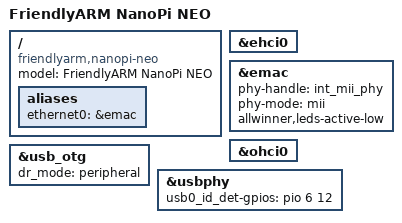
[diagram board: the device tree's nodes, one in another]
#include "sun8i-h3-nanopi.dtsi"
/ {
	model = "FriendlyARM NanoPi NEO";
	compatible = "friendlyarm,nanopi-neo", "allwinner,sun8i-h3";
	aliases {
		ethernet0 = &emac;
	};
};
&ehci0 {
	status = "okay";
};
&emac {
	phy-handle = <&int_mii_phy>;
	phy-mode = "mii";
	allwinner,leds-active-low;
	status = "okay";
};
&ohci0 {
	status = "okay";
};
&usb_otg {
	status = "okay";
	dr_mode = "peripheral";
};
&usbphy {
	usb0_id_det-gpios = <&pio 6 12 GPIO_ACTIVE_HIGH>;  
};
